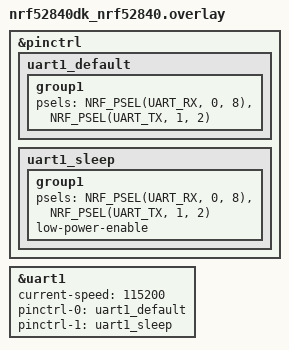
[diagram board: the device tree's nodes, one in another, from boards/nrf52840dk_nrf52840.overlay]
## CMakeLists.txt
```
cmake_minimum_required(VERSION 3.20.0)
find_package(Zephyr REQUIRED HINTS $ENV{ZEPHYR_BASE})

project(ble_heart_sound)

target_sources(app PRIVATE
    src/main.c
    src/heart_sound_service.c
    src/audio_input_service.c
)

target_include_directories(app PRIVATE src)
```

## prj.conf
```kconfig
# =============================================================================
# Digital Stethoscope — nRF52840 BLE peripheral Kconfig
# =============================================================================

# Console
CONFIG_STDOUT_CONSOLE=y
CONFIG_UART_CONSOLE=y
CONFIG_LOG=y
CONFIG_LOG_DEFAULT_LEVEL=3

# Bluetooth
CONFIG_BT=y
CONFIG_BT_PERIPHERAL=y
CONFIG_BT_DEVICE_NAME="HeartSound"
CONFIG_BT_DEVICE_APPEARANCE=833

# GATT server
CONFIG_BT_GATT_CACHING=y
CONFIG_BT_GATT_NOTIFY_MULTIPLE=y
CONFIG_BT_ATT_PREPARE_COUNT=2

# UART — bidirectional with STM32U575:
#   RX: 6-byte classification packets back from STM32
#   TX: 'B' + 16 KB int16 PCM audio windows to STM32 (phone->BLE path)
CONFIG_UART_INTERRUPT_DRIVEN=y

# BLE Data Length Extension + large ATT MTU so the phone can write the
# 16 KB audio window efficiently. With ATT MTU 247 each WRITE_WITHOUT_RESPONSE
# carries up to 244 bytes of PCM (~66 writes per 2-second window).
CONFIG_BT_L2CAP_TX_MTU=247
CONFIG_BT_BUF_ACL_TX_SIZE=251
CONFIG_BT_BUF_ACL_RX_SIZE=251
CONFIG_BT_CTLR_DATA_LENGTH_MAX=251
CONFIG_BT_CTLR_PHY_2M=y

# Minimal footprint
CONFIG_SIZE_OPTIMIZATIONS=y
```

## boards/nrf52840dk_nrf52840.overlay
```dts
/*
 * nRF52840 DK devicetree overlay
 *
 * UART1 carries bidirectional traffic with the STM32U575:
 *   - RX: 6-byte classification packets from STM32 PD5 (USART2 TX, NUCLEO D53)
 *   - TX: 'B' command + 16 KB int16 PCM audio windows to STM32 PD6
 *         (USART2 RX), part of the phone -> BLE -> nRF -> STM32 streaming path
 *
 * nRF52840DK pin connections to STM32 NUCLEO-U575ZI-Q:
 *   nRF P0.08 (UART1 RX) <- STM32 PD5 (USART2 TX, D53)
 *   nRF P1.02 (UART1 TX) -> STM32 PD6 (USART2 RX, D52)
 *   GND <-> GND (common ground between boards)
 *
 * Why P1.02 (not P0.06 or P0.07) for UART1 TX:
 *   The nRF52840 DK ties P0.05/P0.06/P0.07/P0.08 to the onboard J-Link OB
 *   interface UART (RXD/TXD/CTS/RTS) via factory-intact solder bridges
 *   SB5/SB6/SB7/SB8. P0.08 happens to work for RX (J-Link is high-Z there)
 *   but using P0.06 or P0.07 as nRF outputs has the J-Link MCU actively
 *   driving the same line, and the contention silently kills our bytes.
 *   P1.02 is the Zephyr board-file default for uart1_default_alt and is
 *   guaranteed J-Link-free.
 *
 * Zephyr 4.x requires both "default" and "sleep" pinctrl states for
 * nRF UART nodes (pinctrl-0 / pinctrl-1 + pinctrl-names with 2 entries).
 */

&pinctrl {
    uart1_default: uart1_default {
        group1 {
            psels = <NRF_PSEL(UART_RX, 0, 8)>,
                    <NRF_PSEL(UART_TX, 1, 2)>;
        };
    };

    uart1_sleep: uart1_sleep {
        group1 {
            psels = <NRF_PSEL(UART_RX, 0, 8)>,
                    <NRF_PSEL(UART_TX, 1, 2)>;
            low-power-enable;
        };
    };
};

&uart1 {
    status = "okay";
    current-speed = <115200>;
    pinctrl-0 = <&uart1_default>;
    pinctrl-1 = <&uart1_sleep>;
    pinctrl-names = "default", "sleep";
};
```

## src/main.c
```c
/*
 * ble_peripheral/src/main.c — nRF52840 BLE GATT peripheral
 *
 * Receives 6-byte packets from STM32U575 over UART1 and forwards them
 * as BLE GATT notifications to a connected central (phone / nRF Connect app).
 */

#include <zephyr/kernel.h>
#include <zephyr/bluetooth/bluetooth.h>
#include <zephyr/bluetooth/hci.h>
#include <zephyr/bluetooth/conn.h>
#include <zephyr/drivers/uart.h>
#include <zephyr/logging/log.h>

#include "heart_sound_service.h"
#include "audio_input_service.h"

LOG_MODULE_REGISTER(ble_main, LOG_LEVEL_INF);

/* -------------------------------------------------------------------------
 * BLE advertising data
 * ------------------------------------------------------------------------- */
static const struct bt_data ad[] = {
    BT_DATA_BYTES(BT_DATA_FLAGS, (BT_LE_AD_GENERAL | BT_LE_AD_NO_BREDR)),
    BT_DATA(BT_DATA_NAME_COMPLETE, "HeartSound", sizeof("HeartSound") - 1),
};

static struct bt_conn *current_conn;

/* Advertising-restart work.
 *
 * Calling bt_le_adv_start() directly inside the disconnected callback can
 * race with the controller still tearing down the previous connection and
 * fail with -EALREADY / -ENOMEM / -EINVAL — after which the peripheral
 * stops being discoverable until the next reboot. Schedule via the system
 * work queue, with a short initial delay and a retry-on-failure loop, so
 * the peripheral is back on the air within ~100 ms of any disconnect.
 */
static struct k_work_delayable adv_work;

static void adv_work_handler(struct k_work *work)
{
    ARG_UNUSED(work);

    if (current_conn != NULL) {
        /* Already reconnected since the work was scheduled — nothing to do. */
        return;
    }

    int err = bt_le_adv_start(BT_LE_ADV_CONN_FAST_1, ad, ARRAY_SIZE(ad), NULL, 0);
    if (err == 0) {
        LOG_INF("Advertising restarted");
        return;
    }
    if (err == -EALREADY) {
        /* Already advertising — fine. */
        return;
    }

    /* Transient failure (typically -ENOMEM while the stack drains the old
     * connection context). Try again in a moment. */
    LOG_WRN("Advertising start failed (err %d), retrying in 500 ms", err);
    k_work_schedule(&adv_work, K_MSEC(500));
}

static void connected(struct bt_conn *conn, uint8_t err)
{
    if (err) {
        LOG_ERR("Connection failed: %u", err);
        /* Make sure we are back advertising even after a failed pairing. */
        k_work_schedule(&adv_work, K_MSEC(100));
        return;
    }
    current_conn = bt_conn_ref(conn);
    LOG_INF("BLE connected");
}

static void disconnected(struct bt_conn *conn, uint8_t reason)
{
    LOG_INF("BLE disconnected (reason 0x%02x)", reason);
    if (current_conn) {
        bt_conn_unref(current_conn);
        current_conn = NULL;
    }
    /* Schedule restart after a short delay so the controller has time to
     * release the connection slot. The work handler retries on failure. */
    k_work_schedule(&adv_work, K_MSEC(100));
}

BT_CONN_CB_DEFINE(conn_callbacks) = {
    .connected    = connected,
    .disconnected = disconnected,
};

/* -------------------------------------------------------------------------
 * UART receiver — parses 6-byte packets from STM32
 * ------------------------------------------------------------------------- */
static const struct device *uart_dev;
static uint8_t uart_buf[6];
static int uart_buf_pos;

static void uart_rx_cb(const struct device *dev, void *user_data)
{
    ARG_UNUSED(user_data);

    if (!uart_irq_update(dev)) {
        return;
    }

    while (uart_irq_rx_ready(dev)) {
        uint8_t byte;
        int n = uart_fifo_read(dev, &byte, 1);
        if (n <= 0) continue;

        uart_buf[uart_buf_pos++] = byte;

        if (uart_buf_pos == 6) {
            uart_buf_pos = 0;

            uint8_t  class_id    = uart_buf[0];
            uint8_t  confidence  = uart_buf[1];
            uint32_t ts_ms       = (uint32_t)uart_buf[3]
                                 | ((uint32_t)uart_buf[4] << 8)
                                 | ((uint32_t)uart_buf[5] << 16);

            static const char *names[] = {"Absent", "Present", "Unknown"};
            const char *name = (class_id < ARRAY_SIZE(names)) ? names[class_id] : "Invalid";
            LOG_INF("RX: %s  conf=%u%%  ts=%ums", name, confidence, ts_ms);

            if (current_conn) {
                hsc_service_notify(current_conn, class_id, confidence, ts_ms);
            }
        }
    }
}

/* -------------------------------------------------------------------------
 * main
 * ------------------------------------------------------------------------- */
int main(void)
{
    LOG_INF("=== HeartSound BLE Peripheral ===");

    k_work_init_delayable(&adv_work, adv_work_handler);

    /* Init UART */
    uart_dev = DEVICE_DT_GET(DT_NODELABEL(uart1));
    if (device_is_ready(uart_dev)) {
        uart_irq_callback_set(uart_dev, uart_rx_cb);
        uart_irq_rx_enable(uart_dev);
        LOG_INF("UART1 ready (115200 baud)");
    } else {
        LOG_WRN("UART1 not ready");
    }

    /* Init BLE */
    int err = bt_enable(NULL);
    if (err) {
        LOG_ERR("bt_enable failed: %d", err);
        return err;
    }

    hsc_service_init();
    audio_input_service_init(uart_dev);

    /* Start advertising through the same work handler used after a
     * disconnect — keeps one code path responsible for the adv lifecycle
     * and makes initial startup auto-retry too. */
    k_work_schedule(&adv_work, K_NO_WAIT);

    LOG_INF("Advertising as 'HeartSound' — connect with nRF Connect app");
    return 0;
}
```

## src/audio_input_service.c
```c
/*
 * audio_input_service.c — phone -> nRF -> STM32 audio streaming path
 *
 * Implements the AudioIn write handler + 16 KB accumulator + UART forward
 * worker. The GATT characteristic itself is declared inside the single
 * HeartSound primary service in heart_sound_service.c so that both
 * characteristics live under the same primary-service handle (required by
 * Web Bluetooth's getPrimaryService model).
 *
 * UUID of the AudioIn characteristic: 12345678-1234-1234-1234-123456789ABE
 * Properties: WRITE | WRITE_WITHOUT_RESPONSE
 *
 * Phone writes int16 LE PCM (4 kHz mono) in chunks up to (ATT MTU - 3) B
 * each. A full 2-second window is 16000 bytes. When the accumulator fills,
 * we hand it off to a system-workqueue worker that writes 'B' + 16000 bytes
 * to the STM32 on UART1 TX (P1.02 -> STM32 PD6). The STM32 audio_bridge
 * thread runs DSP + INT8 inference and replies via ble_client_send() over
 * USART2 TX (PD5 -> nRF P0.08), which the main UART parser turns into a
 * BLE notification on the classification characteristic.
 */

#include "audio_input_service.h"

#include <zephyr/bluetooth/bluetooth.h>
#include <zephyr/bluetooth/gatt.h>
#include <zephyr/drivers/uart.h>
#include <zephyr/kernel.h>
#include <zephyr/logging/log.h>
#include <string.h>

LOG_MODULE_REGISTER(audio_in, LOG_LEVEL_INF);

#define WINDOW_BYTES   16000U   /* 8000 samples * 2 bytes (int16 LE) */
#define STM32_CMD_AUDIO  'B'    /* 0x42 — matches audio_bridge.c on STM32 */

/* 16 KB accumulator for one audio window. */
static uint8_t s_window[WINDOW_BYTES];
static volatile size_t s_window_pos = 0;
static uint32_t s_window_counter = 0;

/* UART device handle, set by audio_input_service_init(). */
static const struct device *s_uart_to_stm32;

/* Worker that forwards a fully-buffered window over UART. We swap an internal
 * "ready" pointer so the GATT write handler can start filling the next window
 * while the worker drains the current one. */
static uint8_t s_window_ready[WINDOW_BYTES];
static struct k_work s_forward_work;

static void forward_work_handler(struct k_work *work)
{
    ARG_UNUSED(work);

    if (s_uart_to_stm32 == NULL) {
        LOG_WRN("forward: UART device not initialised");
        return;
    }

    uint32_t t0 = k_uptime_get_32();

    uart_poll_out(s_uart_to_stm32, STM32_CMD_AUDIO);
    for (size_t i = 0; i < WINDOW_BYTES; i++) {
        uart_poll_out(s_uart_to_stm32, s_window_ready[i]);
    }

    uint32_t dt = k_uptime_get_32() - t0;
    LOG_INF("forwarded window #%u to STM32 (%u bytes in %u ms)",
            s_window_counter, (unsigned)WINDOW_BYTES, dt);
}

ssize_t audio_input_write(struct bt_conn *conn,
                          const struct bt_gatt_attr *attr,
                          const void *buf, uint16_t len,
                          uint16_t offset, uint8_t flags)
{
    ARG_UNUSED(conn);
    ARG_UNUSED(attr);
    ARG_UNUSED(flags);

    if (offset != 0) {
        return BT_GATT_ERR(BT_ATT_ERR_INVALID_OFFSET);
    }
    if (len == 0) {
        return 0;
    }

    /* Disallow concurrent fills while a previous window is being forwarded.
     * The window swap below clears s_window_pos before re-enabling fills. */
    size_t pos = s_window_pos;
    size_t space = (pos < WINDOW_BYTES) ? (WINDOW_BYTES - pos) : 0;
    if (space == 0) {
        /* Drop — previous window not yet handed off. The phone-side client
         * should pace its writes so this doesn't happen, but never crash. */
        LOG_WRN("audio_in_write: window full, dropping %u bytes", len);
        return len;
    }

    size_t copy = (len < space) ? len : space;
    memcpy(&s_window[pos], buf, copy);
    pos += copy;
    s_window_pos = pos;

    if (pos >= WINDOW_BYTES) {
        /* Swap buffers: copy filled window into the worker's buffer, reset
         * the accumulator so the phone can start writing the next window
         * immediately. */
        memcpy(s_window_ready, s_window, WINDOW_BYTES);
        s_window_pos = 0;
        s_window_counter++;
        k_work_submit(&s_forward_work);
    }

    return copy;
}

void audio_input_service_init(const struct device *uart_to_stm32)
{
    s_uart_to_stm32 = uart_to_stm32;
    k_work_init(&s_forward_work, forward_work_handler);
    LOG_INF("AudioIn accumulator ready (16 KB window, write_without_response)");
}
```

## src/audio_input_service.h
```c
#ifndef AUDIO_INPUT_SERVICE_H
#define AUDIO_INPUT_SERVICE_H

#include <stdint.h>
#include <zephyr/bluetooth/conn.h>
#include <zephyr/bluetooth/gatt.h>
#include <zephyr/device.h>

/* Audio Input characteristic UUID (declared inside the single
 * HeartSound primary service in heart_sound_service.c):
 *   12345678-1234-1234-1234-123456789ABE
 *
 * Phone writes chunks of int16 LE PCM (4 kHz mono) into this characteristic
 * using WRITE_WITHOUT_RESPONSE. Each window is 16000 bytes = 8000 samples.
 *
 * When a complete window is accumulated, the service forwards 'B' + the
 * 16 KB payload to the STM32U575 over UART1 TX (P1.02 -> STM32 PD6).
 * The STM32 runs DSP + INT8 inference and sends the classification back
 * over UART1 RX (P0.08) as a 6-byte packet, which the main UART parser
 * already turns into a BLE notification on the classification
 * characteristic.
 *
 * To keep all characteristics inside a SINGLE primary GATT service
 * (required by Web Bluetooth's getPrimaryService model), this module
 * does NOT declare its own BT_GATT_SERVICE_DEFINE block. Instead it
 * exposes the write handler so heart_sound_service.c can include the
 * audio-in characteristic alongside the classification one.
 */

/* GATT write handler for the AudioIn characteristic. */
ssize_t audio_input_write(struct bt_conn *conn,
                          const struct bt_gatt_attr *attr,
                          const void *buf, uint16_t len,
                          uint16_t offset, uint8_t flags);

/* Initialise the accumulator + the UART forward worker. Must be called
 * once from main() before BLE advertising starts. */
void audio_input_service_init(const struct device *uart_to_stm32);

#endif /* AUDIO_INPUT_SERVICE_H */
```

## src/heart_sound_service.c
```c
/*
 * heart_sound_service.c — Custom BLE GATT service
 *
 * Service UUID:        12345678-1234-1234-1234-123456789ABC
 * Characteristic UUID: 12345678-1234-1234-1234-123456789ABD
 *   Properties: NOTIFY
 *   Format: short printable ASCII string, e.g. "Present 95%"
 *   nRF Connect auto-renders ASCII payloads as text in the notification feed.
 *
 * class_id encoding (CirCor 2022, 3-class):
 *   0x00 = Absent
 *   0x01 = Present
 *   0x02 = Unknown
 *   0xFF = Error
 */

#include "heart_sound_service.h"
#include "audio_input_service.h"

#include <zephyr/bluetooth/bluetooth.h>
#include <zephyr/bluetooth/gatt.h>
#include <zephyr/logging/log.h>
#include <stdio.h>

LOG_MODULE_REGISTER(hsc_service, LOG_LEVEL_INF);

/* Custom service UUID: 12345678-1234-1234-1234-123456789ABC */
#define BT_UUID_HSC_SERVICE_VAL \
    BT_UUID_128_ENCODE(0x12345678, 0x1234, 0x1234, 0x1234, 0x123456789ABCULL)

/* Classification (notify) characteristic UUID: ...ABD */
#define BT_UUID_HSC_RESULT_VAL \
    BT_UUID_128_ENCODE(0x12345678, 0x1234, 0x1234, 0x1234, 0x123456789ABDULL)

/* Audio-in (write_without_response) characteristic UUID: ...ABE */
#define BT_UUID_HSC_AUDIO_IN_VAL \
    BT_UUID_128_ENCODE(0x12345678, 0x1234, 0x1234, 0x1234, 0x123456789ABEULL)

static struct bt_uuid_128 hsc_service_uuid  = BT_UUID_INIT_128(BT_UUID_HSC_SERVICE_VAL);
static struct bt_uuid_128 hsc_result_uuid   = BT_UUID_INIT_128(BT_UUID_HSC_RESULT_VAL);
static struct bt_uuid_128 hsc_audio_in_uuid = BT_UUID_INIT_128(BT_UUID_HSC_AUDIO_IN_VAL);

/* Notification subscriber tracking */
static struct bt_gatt_indicate_params indicate_params;
static bool notify_enabled = false;

static void hsc_ccc_changed(const struct bt_gatt_attr *attr, uint16_t value)
{
    notify_enabled = (value == BT_GATT_CCC_NOTIFY);
    LOG_INF("HSC notifications %s", notify_enabled ? "enabled" : "disabled");
}

/* Single GATT service that holds BOTH characteristics. Web Bluetooth's
 * service.getCharacteristic() only searches the one primary service handle
 * returned by getPrimaryService(uuid) — splitting the service across two
 * BT_GATT_SERVICE_DEFINE blocks made the audio-in characteristic invisible
 * to Web Bluetooth clients. Keep everything inside this one declaration.
 */
BT_GATT_SERVICE_DEFINE(hsc_svc,
    BT_GATT_PRIMARY_SERVICE(&hsc_service_uuid),

    /* Classification notify characteristic - existing behavior. */
    BT_GATT_CHARACTERISTIC(&hsc_result_uuid.uuid,
                           BT_GATT_CHRC_NOTIFY,
                           BT_GATT_PERM_NONE,
                           NULL, NULL, NULL),
    BT_GATT_CUD("Heart Sound Classification", BT_GATT_PERM_READ),
    BT_GATT_CCC(hsc_ccc_changed,
                BT_GATT_PERM_READ | BT_GATT_PERM_WRITE),

    /* Audio-in write characteristic - new phone-as-mic streaming path.
     * Handler implementation lives in audio_input_service.c. */
    BT_GATT_CHARACTERISTIC(&hsc_audio_in_uuid.uuid,
                           BT_GATT_CHRC_WRITE | BT_GATT_CHRC_WRITE_WITHOUT_RESP,
                           BT_GATT_PERM_WRITE,
                           NULL, audio_input_write, NULL),
    BT_GATT_CUD("Audio In (4 kHz int16 mono, 16 KB / 2 s window)",
                BT_GATT_PERM_READ),
);

/* -------------------------------------------------------------------------
 * Public API
 * ------------------------------------------------------------------------- */
void hsc_service_init(void)
{
    LOG_INF("Heart Sound Classification service registered");
}

int hsc_service_notify(struct bt_conn *conn,
                       uint8_t class_id, uint8_t confidence,
                       uint32_t timestamp_ms)
{
    ARG_UNUSED(timestamp_ms);

    if (!notify_enabled) {
        return -ENOTCONN;
    }

    static const char *const class_names[] = {"Absent", "Present", "Unknown"};
    const char *name = (class_id < ARRAY_SIZE(class_names))
                           ? class_names[class_id]
                           : "Error";

    /* Printable ASCII payload — e.g. "Present 95%" (no trailing NUL).
     * nRF Connect renders this as text in the notification log line. */
    char pkt[20];
    int len = snprintf(pkt, sizeof(pkt), "%s %u%%", name, confidence);
    if (len < 0) {
        return -EINVAL;
    }
    if (len > (int)sizeof(pkt)) {
        len = sizeof(pkt);
    }

    /* Characteristic value attribute (index 1 in the service table). */
    const struct bt_gatt_attr *attr = &hsc_svc.attrs[1];

    struct bt_gatt_notify_params params = {
        .attr = attr,
        .data = pkt,
        .len  = (uint16_t)len,
    };

    int err = bt_gatt_notify_cb(conn, &params);
    if (err) {
        LOG_ERR("Notify failed: %d", err);
    }
    return err;
}
```

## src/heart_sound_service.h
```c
#ifndef HEART_SOUND_SERVICE_H
#define HEART_SOUND_SERVICE_H

#include <stdint.h>
#include <zephyr/bluetooth/conn.h>

void hsc_service_init(void);

int hsc_service_notify(struct bt_conn *conn,
                       uint8_t class_id, uint8_t confidence,
                       uint32_t timestamp_ms);

#endif /* HEART_SOUND_SERVICE_H */
```
